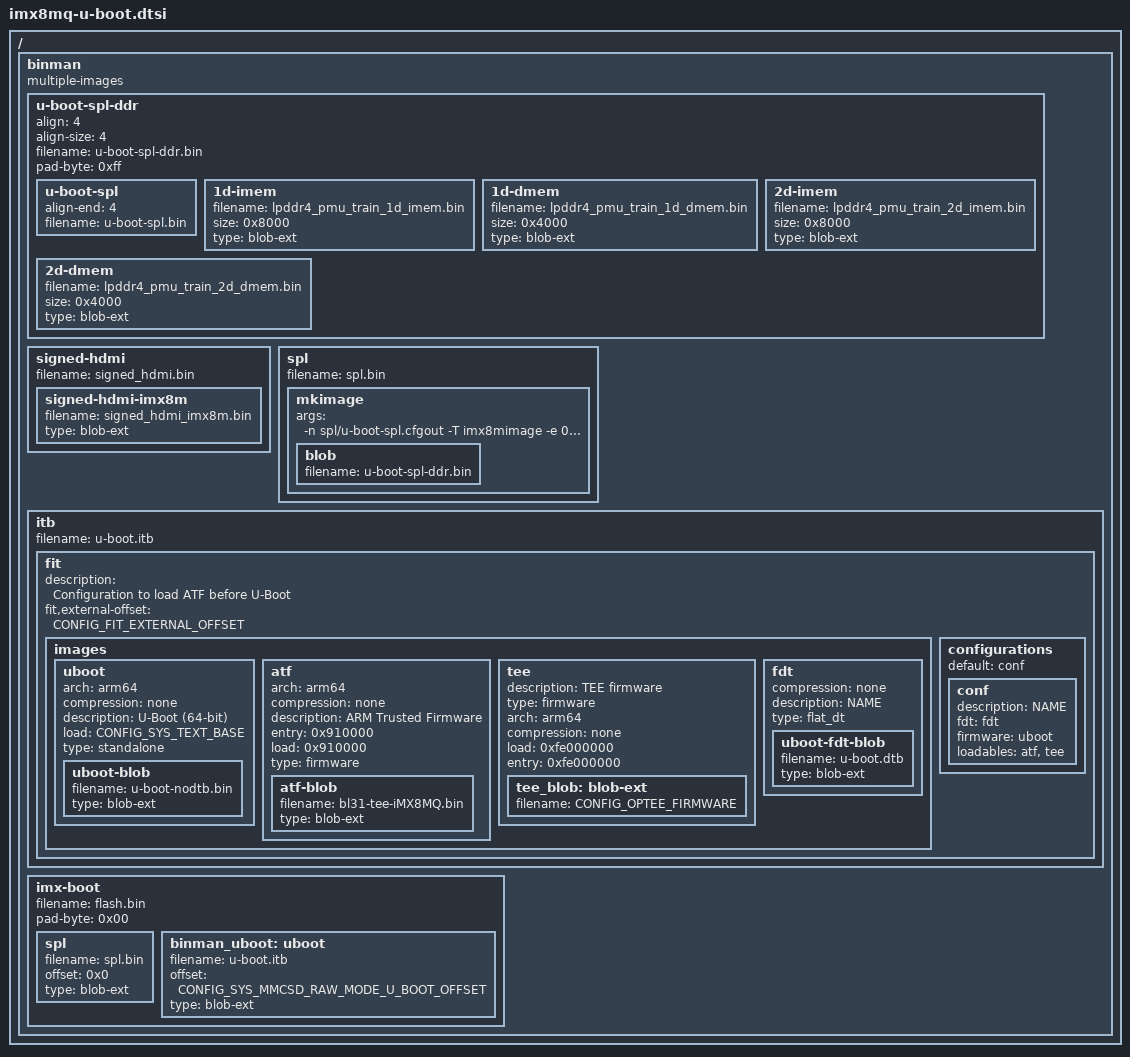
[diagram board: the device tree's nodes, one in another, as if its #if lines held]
// SPDX-License-Identifier: GPL-2.0+
/*
 * Copyright 2021 NXP
 */

/ {
	binman: binman {
		multiple-images;
	};

};

&binman {
	u-boot-spl-ddr {
		align = <4>;
		align-size = <4>;
		filename = "u-boot-spl-ddr.bin";
		pad-byte = <0xff>;

		u-boot-spl {
			align-end = <4>;
			filename = "u-boot-spl.bin";
		};

		1d-imem {
			filename = "lpddr4_pmu_train_1d_imem.bin";
			size = <0x8000>;
			type = "blob-ext";
		};

		1d-dmem {
			filename = "lpddr4_pmu_train_1d_dmem.bin";
			size = <0x4000>;
			type = "blob-ext";
		};

		2d-imem {
			filename = "lpddr4_pmu_train_2d_imem.bin";
			size = <0x8000>;
			type = "blob-ext";
		};

		2d-dmem {
			filename = "lpddr4_pmu_train_2d_dmem.bin";
			size = <0x4000>;
			type = "blob-ext";
		};
	};

	signed-hdmi {
		filename = "signed_hdmi.bin";

		signed-hdmi-imx8m {
			filename = "signed_hdmi_imx8m.bin";
			type = "blob-ext";
		};
	};

	spl {
		filename = "spl.bin";

		mkimage {
			args = "-n spl/u-boot-spl.cfgout -T imx8mimage -e 0x7e1000";

			blob {
				filename = "u-boot-spl-ddr.bin";
			};
		};
	};

	itb {
		filename = "u-boot.itb";

		fit {
			description = "Configuration to load ATF before U-Boot";
			fit,external-offset = <CONFIG_FIT_EXTERNAL_OFFSET>;
			#address-cells = <1>;

			images {
				uboot {
					arch = "arm64";
					compression = "none";
					description = "U-Boot (64-bit)";
					load = <CONFIG_SYS_TEXT_BASE>;
					type = "standalone";

					uboot-blob {
						filename = "u-boot-nodtb.bin";
						type = "blob-ext";
					};
				};

				atf {
					arch = "arm64";
					compression = "none";
					description = "ARM Trusted Firmware";
					entry = <0x910000>;
					load = <0x910000>;
					type = "firmware";

					atf-blob {
#ifdef CONFIG_OPTEE_FIRMWARE_SET
						filename = "bl31-tee-iMX8MQ.bin";
#else
						filename = "bl31-iMX8MQ.bin";
#endif
						type = "blob-ext";
					};
				};

#ifdef CONFIG_OPTEE_FIRMWARE_SET
				tee {
					description = "TEE firmware";
					type = "firmware";
					arch = "arm64";
					compression = "none";
					load = <0xfe000000>;
					entry = <0xfe000000>;

					tee_blob: blob-ext {
						filename = CONFIG_OPTEE_FIRMWARE;
					};
				};
#endif
				fdt {
					compression = "none";
					description = "NAME";
					type = "flat_dt";

					uboot-fdt-blob {
						filename = "u-boot.dtb";
						type = "blob-ext";
					};
				};
			};

			configurations {
				default = "conf";

				conf {
					description = "NAME";
					fdt = "fdt";
					firmware = "uboot";
#ifdef CONFIG_OPTEE_FIRMWARE_SET
					loadables = "atf", "tee";
#else
					loadables = "atf";
#endif
				};
			};
		};
	};

	imx-boot {
		filename = "flash.bin";
		pad-byte = <0x00>;

		spl {
			filename = "spl.bin";
			offset = <0x0>;
			type = "blob-ext";
		};

		binman_uboot: uboot {
			filename = "u-boot.itb";
#if defined(CONFIG_SYS_MMCSD_RAW_MODE_U_BOOT_USE_OFFSET)
			offset = <CONFIG_SYS_MMCSD_RAW_MODE_U_BOOT_OFFSET>;
#else
			offset = <0x57c00>;
#endif
			type = "blob-ext";
		};
	};
};
